VERSION ""

NS_ :

BS_:

BU_:

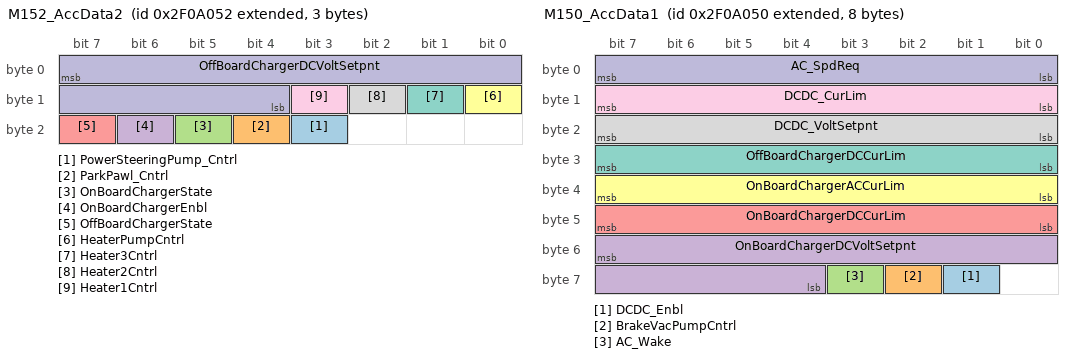
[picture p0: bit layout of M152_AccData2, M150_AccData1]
BO_ 2196807762 M152_AccData2: 3 Vector__XXX
 SG_ PowerSteeringPump_Cntrl : 19|1@0+ (1,0) [0|1] "unitless:" Vector__XXX
 SG_ ParkPawl_Cntrl : 20|1@0+ (1,0) [0|1] "unitless:" Vector__XXX
 SG_ OnBoardChargerState : 21|1@0+ (1,0) [0|1] "unitless:" Vector__XXX
 SG_ OnBoardChargerEnbl : 22|1@0+ (1,0) [0|1] "unitless:" Vector__XXX
 SG_ OffBoardChargerState : 23|1@0+ (1,0) [0|1] "unitless:" Vector__XXX
 SG_ HeaterPumpCntrl : 8|1@0+ (1,0) [0|1] "unitless:" Vector__XXX
 SG_ Heater3Cntrl : 9|1@0+ (1,0) [0|1] "unitless:" Vector__XXX
 SG_ Heater2Cntrl : 10|1@0+ (1,0) [0|1] "unitless:" Vector__XXX
 SG_ Heater1Cntrl : 11|1@0+ (1,0) [0|1] "unitless:" Vector__XXX
 SG_ OffBoardChargerDCVoltSetpnt : 7|12@0+ (0.5,0) [0|2047.5] "voltage:V" Vector__XXX

BO_ 2196807760 M150_AccData1: 8 Vector__XXX
 SG_ DCDC_Enbl : 57|1@0+ (1,0) [0|1] "unitless:" Vector__XXX
 SG_ BrakeVacPumpCntrl : 58|1@0+ (1,0) [0|1] "unitless:" Vector__XXX
 SG_ AC_Wake : 59|1@0+ (1,0) [0|1] "unitless:" Vector__XXX
 SG_ OnBoardChargerDCVoltSetpnt : 55|12@0+ (0.5,0) [0|2047.5] "voltage:V" Vector__XXX
 SG_ OnBoardChargerDCCurLim : 47|8@0+ (0.5,0) [0|127.5] "current:A" Vector__XXX
 SG_ OnBoardChargerACCurLim : 39|8@0+ (0.5,0) [0|127.5] "current:A" Vector__XXX
 SG_ OffBoardChargerDCCurLim : 31|8@0+ (0.5,0) [0|127.5] "current:A" Vector__XXX
 SG_ DCDC_VoltSetpnt : 23|8@0+ (0.1,0) [0|25.5] "voltage:V" Vector__XXX
 SG_ DCDC_CurLim : 15|8@0+ (0.5,0) [0|127.5] "current:A" Vector__XXX
 SG_ AC_SpdReq : 7|8@0+ (25,0) [0|6375] "angular_speed:rpm" Vector__XXX

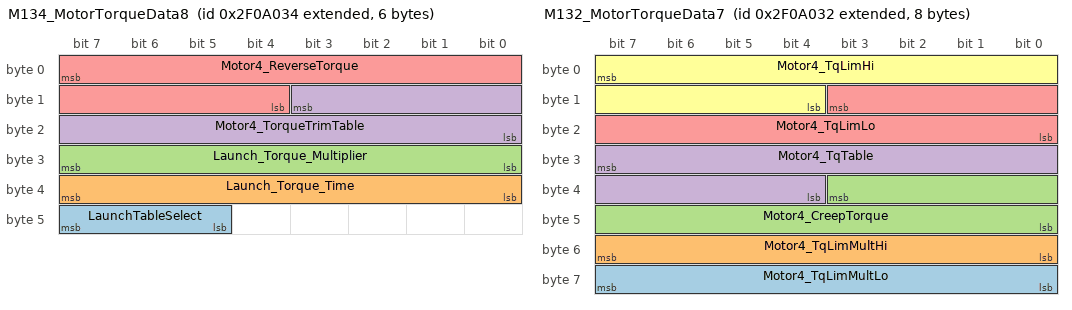
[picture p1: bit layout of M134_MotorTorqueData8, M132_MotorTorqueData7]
BO_ 2196807732 M134_MotorTorqueData8: 6 Vector__XXX
 SG_ LaunchTableSelect : 47|3@0+ (1,0) [0|7] "unitless:" Vector__XXX
 SG_ Launch_Torque_Time : 39|8@0+ (0.1,0) [0|25.5] "time:s" Vector__XXX
 SG_ Launch_Torque_Multiplier : 31|8@0+ (1,0) [0|255] "fraction:%" Vector__XXX
 SG_ Motor4_TorqueTrimTable : 11|12@0- (0.001,0) [-2.048|2.047] "fraction:frac" Vector__XXX
 SG_ Motor4_ReverseTorque : 7|12@0+ (0.1,0) [0|409.5] "torque:N.m" Vector__XXX

BO_ 2196807730 M132_MotorTorqueData7: 8 Vector__XXX
 SG_ Motor4_TqLimMultLo : 63|8@0+ (0.005,0) [0|1.275] "fraction:frac" Vector__XXX
 SG_ Motor4_TqLimMultHi : 55|8@0+ (0.005,0) [0|1.275] "fraction:frac" Vector__XXX
 SG_ Motor4_CreepTorque : 35|12@0+ (0.1,0) [0|409.5] "torque:N.m" Vector__XXX
 SG_ Motor4_TqTable : 31|12@0+ (0.5,0) [0|2047.5] "torque:N.m" Vector__XXX
 SG_ Motor4_TqLimLo : 11|12@0- (0.5,0) [-1024|1023.5] "torque:N.m" Vector__XXX
 SG_ Motor4_TqLimHi : 7|12@0+ (0.5,0) [0|2047.5] "torque:N.m" Vector__XXX

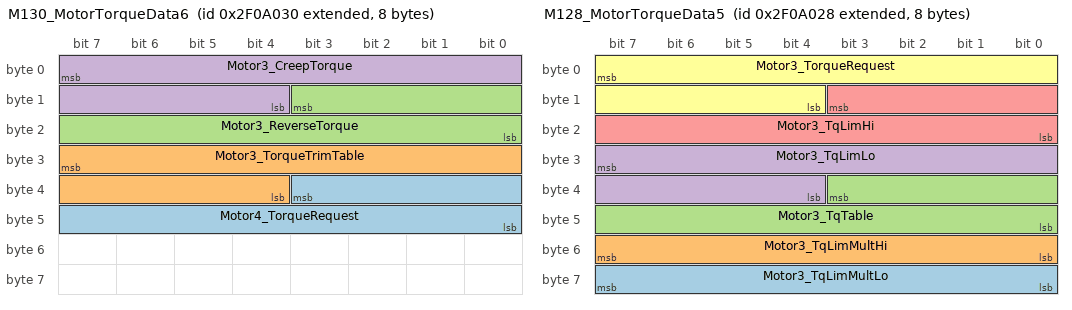
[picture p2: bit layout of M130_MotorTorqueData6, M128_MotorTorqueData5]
BO_ 2196807728 M130_MotorTorqueData6: 8 Vector__XXX
 SG_ Motor4_TorqueRequest : 35|12@0- (0.5,0) [-1024|1023.5] "torque:N.m" Vector__XXX
 SG_ Motor3_TorqueTrimTable : 31|12@0- (0.001,0) [-2.048|2.047] "fraction:frac" Vector__XXX
 SG_ Motor3_ReverseTorque : 11|12@0+ (0.1,0) [0|409.5] "torque:N.m" Vector__XXX
 SG_ Motor3_CreepTorque : 7|12@0+ (0.1,0) [0|409.5] "torque:N.m" Vector__XXX

BO_ 2196807720 M128_MotorTorqueData5: 8 Vector__XXX
 SG_ Motor3_TqLimMultLo : 63|8@0+ (0.005,0) [0|1.275] "fraction:frac" Vector__XXX
 SG_ Motor3_TqLimMultHi : 55|8@0+ (0.005,0) [0|1.275] "fraction:frac" Vector__XXX
 SG_ Motor3_TqTable : 35|12@0+ (0.5,0) [0|2047.5] "torque:N.m" Vector__XXX
 SG_ Motor3_TqLimLo : 31|12@0- (0.5,0) [-1024|1023.5] "torque:N.m" Vector__XXX
 SG_ Motor3_TqLimHi : 11|12@0+ (0.5,0) [0|2047.5] "torque:N.m" Vector__XXX
 SG_ Motor3_TorqueRequest : 7|12@0- (0.5,0) [-1024|1023.5] "torque:N.m" Vector__XXX

BO_ 2196807752 M148_VCU_FaultStates3_Reserved: 8 Vector__XXX

BO_ 2196807704 M118_VehicleInputs4: 4 Vector__XXX
 SG_ Vehicle_Odometer : 7|32@0+ (0.01,0) [0|42949672.95] "distance:mi" Vector__XXX

BO_ 2196807696 M110_DriverInputs3_Reserved: 8 Vector__XXX

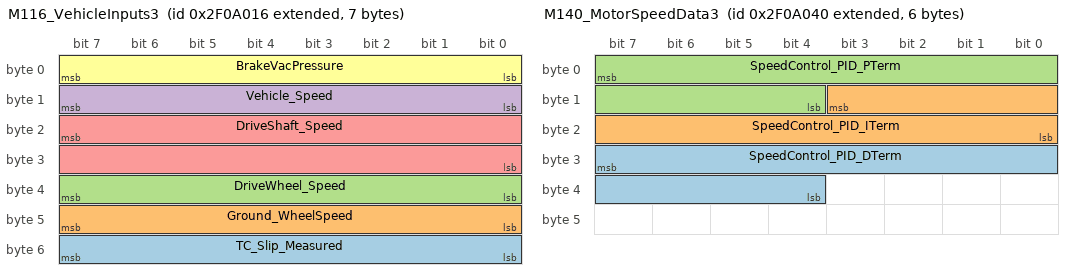
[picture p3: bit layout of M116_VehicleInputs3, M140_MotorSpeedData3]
BO_ 2196807702 M116_VehicleInputs3: 7 Vector__XXX
 SG_ TC_Slip_Measured : 55|8@0+ (1,0) [0|255] "speed:mph" Vector__XXX
 SG_ Ground_WheelSpeed : 47|8@0+ (1,0) [0|255] "speed:mph" Vector__XXX
 SG_ DriveWheel_Speed : 39|8@0+ (1,0) [0|255] "speed:mph" Vector__XXX
 SG_ Vehicle_Speed : 15|8@0+ (1,0) [0|255] "speed:mph" Vector__XXX
 SG_ DriveShaft_Speed : 23|16@0+ (1,0) [0|65535] "angular_speed:rpm" Vector__XXX
 SG_ BrakeVacPressure : 7|8@0+ (0.14504,-14.696) [-14.696|22.2892] "pressure_gauge:psi(g)" Vector__XXX

BO_ 2196807684 M104_VCU_States3: 8 Vector__XXX
 SG_ Run_Time_Counter : 55|16@0+ (1,0) [0|65535] "time:s" Vector__XXX
 SG_ LaunchRamp_Time : 47|8@0+ (0.1,0) [0|25.5] "time:s" Vector__XXX
 SG_ LaunchTimer_Running : 33|1@0+ (1,0) [0|1] "unitless:" Vector__XXX
 SG_ LimMult_MC4CurrRamp_Active : 34|1@0+ (1,0) [0|1] "unitless:" Vector__XXX
 SG_ LimMult_MC3CurrRamp_Active : 35|1@0+ (1,0) [0|1] "unitless:" Vector__XXX
 SG_ LimMult_MC2CurrRamp_Active : 36|1@0+ (1,0) [0|1] "unitless:" Vector__XXX
 SG_ LimMult_MC1CurrRamp_Active : 37|1@0+ (1,0) [0|1] "unitless:" Vector__XXX
 SG_ LimMult_VehSpd_Lo_Active : 38|1@0+ (1,0) [0|1] "unitless:" Vector__XXX
 SG_ LimMult_VehSpd_Hi_Active : 39|1@0+ (1,0) [0|1] "unitless:" Vector__XXX
 SG_ LimMult_Shift5_Tq_Active : 24|1@0+ (1,0) [0|1] "unitless:" Vector__XXX
 SG_ LimMult_Shift4_Tq_Active : 25|1@0+ (1,0) [0|1] "unitless:" Vector__XXX
 SG_ LimMult_Shift3_Tq_Active : 26|1@0+ (1,0) [0|1] "unitless:" Vector__XXX
 SG_ LimMult_Shift2_Tq_Active : 27|1@0+ (1,0) [0|1] "unitless:" Vector__XXX
 SG_ LimMult_Shift1_Tq_Active : 28|1@0+ (1,0) [0|1] "unitless:" Vector__XXX
 SG_ LimMult_Pack_Voltage_Active : 29|1@0+ (1,0) [0|1] "unitless:" Vector__XXX
 SG_ LimMult_Pack_TempLo_Active : 30|1@0+ (1,0) [0|1] "unitless:" Vector__XXX
 SG_ LimMult_Pack_TempHi_Active : 31|1@0+ (1,0) [0|1] "unitless:" Vector__XXX
 SG_ LimMult_Pack_Current_Active : 16|1@0+ (1,0) [0|1] "unitless:" Vector__XXX
 SG_ LimMult_Over_rev_Active : 17|1@0+ (1,0) [0|1] "unitless:" Vector__XXX
 SG_ LimMult_Motor4_Temp_Active : 18|1@0+ (1,0) [0|1] "unitless:" Vector__XXX
 SG_ LimMult_Motor4_SpdLo_Active : 19|1@0+ (1,0) [0|1] "unitless:" Vector__XXX
 SG_ LimMult_Motor3_Temp_Active : 20|1@0+ (1,0) [0|1] "unitless:" Vector__XXX
 SG_ LimMult_Motor3_SpdLo_Active : 21|1@0+ (1,0) [0|1] "unitless:" Vector__XXX
 SG_ LimMult_Motor2_Temp_Active : 22|1@0+ (1,0) [0|1] "unitless:" Vector__XXX
 SG_ LimMult_Motor2_SpdLo_Active : 23|1@0+ (1,0) [0|1] "unitless:" Vector__XXX
 SG_ LimMult_Motor1_Temp_Active : 8|1@0+ (1,0) [0|1] "unitless:" Vector__XXX
 SG_ LimMult_Motor1_SpdLo_Active : 9|1@0+ (1,0) [0|1] "unitless:" Vector__XXX
 SG_ LimMult_MC4Temp_Active : 10|1@0+ (1,0) [0|1] "unitless:" Vector__XXX
 SG_ LimMult_MC4Curr_Active : 11|1@0+ (1,0) [0|1] "unitless:" Vector__XXX
 SG_ LimMult_MC3Temp_Active : 12|1@0+ (1,0) [0|1] "unitless:" Vector__XXX
 SG_ LimMult_MC3Curr_Active : 13|1@0+ (1,0) [0|1] "unitless:" Vector__XXX
 SG_ LimMult_MC2Temp_Active : 14|1@0+ (1,0) [0|1] "unitless:" Vector__XXX
 SG_ LimMult_MC2Curr_Active : 15|1@0+ (1,0) [0|1] "unitless:" Vector__XXX
 SG_ LimMult_MC1Temp_Active : 0|1@0+ (1,0) [0|1] "unitless:" Vector__XXX
 SG_ LimMult_MC1Curr_Active : 1|1@0+ (1,0) [0|1] "unitless:" Vector__XXX
 SG_ LimMult_Launch_Time_Active : 2|1@0+ (1,0) [0|1] "unitless:" Vector__XXX
 SG_ LimMult_DriveShaft_Spd_Active : 3|1@0+ (1,0) [0|1] "unitless:" Vector__XXX
 SG_ LimMult_CellVolt_Min_Active : 4|1@0+ (1,0) [0|1] "unitless:" Vector__XXX
 SG_ LimMult_CellVolt_Max_Active : 5|1@0+ (1,0) [0|1] "unitless:" Vector__XXX
 SG_ LimMult_Batt_SOC_Active : 6|1@0+ (1,0) [0|1] "unitless:" Vector__XXX
 SG_ LimMult_Batt_DCL_Active : 7|1@0+ (1,0) [0|1] "unitless:" Vector__XXX

BO_ 2196807746 M142_MotorSpeedData4_Reserved: 8 Vector__XXX

BO_ 2196807744 M140_MotorSpeedData3: 6 Vector__XXX
 SG_ SpeedControl_PID_DTerm : 31|12@0- (0.5,0) [-1024|1023.5] "torque:N.m" Vector__XXX
 SG_ SpeedControl_PID_ITerm : 11|12@0- (0.5,0) [-1024|1023.5] "torque:N.m" Vector__XXX
 SG_ SpeedControl_PID_PTerm : 7|12@0- (0.5,0) [-1024|1023.5] "torque:N.m" Vector__XXX

BO_ 2196807750 M146_VCU_FaultStates2_Reserved: 8 Vector__XXX

BO_ 2196807748 M144_VCU_FaultStates1: 7 Vector__XXX
 SG_ Fault_Wheel_Speed_NR_Spike : 48|1@0+ (1,0) [0|1] "unitless:" Vector__XXX
 SG_ Fault_Wheel_Speed_NL_Spike : 49|1@0+ (1,0) [0|1] "unitless:" Vector__XXX
 SG_ Fault_Wheel_Speed_DR_Spike : 50|1@0+ (1,0) [0|1] "unitless:" Vector__XXX
 SG_ Fault_Wheel_Speed_DL_Spike : 51|1@0+ (1,0) [0|1] "unitless:" Vector__XXX
 SG_ Fault_Wheel_Speed_DD_Spike : 52|1@0+ (1,0) [0|1] "unitless:" Vector__XXX
 SG_ Fault_WheelBar_Press2_InputLo : 53|1@0+ (1,0) [0|1] "unitless:" Vector__XXX
 SG_ Fault_WheelBar_Press2_InputHi : 54|1@0+ (1,0) [0|1] "unitless:" Vector__XXX
 SG_ Fault_WheelBar_Press1_InputLo : 55|1@0+ (1,0) [0|1] "unitless:" Vector__XXX
 SG_ Fault_WheelBar_Press1_InputHi : 40|1@0+ (1,0) [0|1] "unitless:" Vector__XXX
 SG_ Fault_Trans_Temp_InputLo : 41|1@0+ (1,0) [0|1] "unitless:" Vector__XXX
 SG_ Fault_Trans_Temp_InputHi : 42|1@0+ (1,0) [0|1] "unitless:" Vector__XXX
 SG_ Fault_Trans_Press_InputLo : 43|1@0+ (1,0) [0|1] "unitless:" Vector__XXX
 SG_ Fault_Trans_Press_InputHi : 44|1@0+ (1,0) [0|1] "unitless:" Vector__XXX
 SG_ Fault_TransBrk_Sol : 45|1@0+ (1,0) [0|1] "unitless:" Vector__XXX
 SG_ Fault_Shift_Sol : 46|1@0+ (1,0) [0|1] "unitless:" Vector__XXX
 SG_ Fault_Reverse_Lamps : 47|1@0+ (1,0) [0|1] "unitless:" Vector__XXX
 SG_ Fault_Regen_LeverXChk : 32|1@0+ (1,0) [0|1] "unitless:" Vector__XXX
 SG_ Fault_Park_Lamps : 33|1@0+ (1,0) [0|1] "unitless:" Vector__XXX
 SG_ Fault_Manual_Regen2_Spike : 34|1@0+ (1,0) [0|1] "unitless:" Vector__XXX
 SG_ Fault_Manual_Regen2_InputLo : 35|1@0+ (1,0) [0|1] "unitless:" Vector__XXX
 SG_ Fault_Manual_Regen2_InputHi : 36|1@0+ (1,0) [0|1] "unitless:" Vector__XXX
 SG_ Fault_Manual_Regen1_Spike : 37|1@0+ (1,0) [0|1] "unitless:" Vector__XXX
 SG_ Fault_Manual_Regen1_InputLo : 38|1@0+ (1,0) [0|1] "unitless:" Vector__XXX
 SG_ Fault_Manual_Regen1_InputHi : 39|1@0+ (1,0) [0|1] "unitless:" Vector__XXX
 SG_ Fault_LineLock_Sol : 24|1@0+ (1,0) [0|1] "unitless:" Vector__XXX
 SG_ Fault_MC5SupplyVoltageLow : 25|1@0+ (1,0) [0|1] "unitless:" Vector__XXX
 SG_ Fault_MC4SupplyVoltageLow : 26|1@0+ (1,0) [0|1] "unitless:" Vector__XXX
 SG_ Fault_MC4_Contactor : 27|1@0+ (1,0) [0|1] "unitless:" Vector__XXX
 SG_ Fault_MC3SupplyVoltageLow : 28|1@0+ (1,0) [0|1] "unitless:" Vector__XXX
 SG_ Fault_MC3_Contactor : 29|1@0+ (1,0) [0|1] "unitless:" Vector__XXX
 SG_ Fault_MC2SupplyVoltageLow : 30|1@0+ (1,0) [0|1] "unitless:" Vector__XXX
 SG_ Fault_MC2_Contactor : 31|1@0+ (1,0) [0|1] "unitless:" Vector__XXX
 SG_ Fault_MC1SupplyVoltageLow : 16|1@0+ (1,0) [0|1] "unitless:" Vector__XXX
 SG_ Fault_MC1_Contactor : 17|1@0+ (1,0) [0|1] "unitless:" Vector__XXX
 SG_ Fault_IgnChgPlug_XCheck : 18|1@0+ (1,0) [0|1] "unitless:" Vector__XXX
 SG_ Fault_Idle_Target : 19|1@0+ (1,0) [0|1] "unitless:" Vector__XXX
 SG_ Fault_Head_Lamps : 20|1@0+ (1,0) [0|1] "unitless:" Vector__XXX
 SG_ Fault_DCVoltage_SafeLight : 21|1@0+ (1,0) [0|1] "unitless:" Vector__XXX
 SG_ Fault_Cool_Temp2_InputLo : 22|1@0+ (1,0) [0|1] "unitless:" Vector__XXX
 SG_ Fault_Cool_Temp2_InputHi : 23|1@0+ (1,0) [0|1] "unitless:" Vector__XXX
 SG_ Fault_Cool_Temp1_InputLo : 8|1@0+ (1,0) [0|1] "unitless:" Vector__XXX
 SG_ Fault_Cool_Temp1_InputHi : 9|1@0+ (1,0) [0|1] "unitless:" Vector__XXX
 SG_ Fault_Cooling_Pump2 : 10|1@0+ (1,0) [0|1] "unitless:" Vector__XXX
 SG_ Fault_Cooling_Pump1 : 11|1@0+ (1,0) [0|1] "unitless:" Vector__XXX
 SG_ Fault_Brk_Press_InputLo : 12|1@0+ (1,0) [0|1] "unitless:" Vector__XXX
 SG_ Fault_Brk_Press_InputHi : 13|1@0+ (1,0) [0|1] "unitless:" Vector__XXX
 SG_ Fault_Brake_Lamps : 14|1@0+ (1,0) [0|1] "unitless:" Vector__XXX
 SG_ Fault_AccelPedal_XCheck : 15|1@0+ (1,0) [0|1] "unitless:" Vector__XXX
 SG_ Fault_AccPedal2_Spike : 0|1@0+ (1,0) [0|1] "unitless:" Vector__XXX
 SG_ Fault_AccPedal2_InputLo : 1|1@0+ (1,0) [0|1] "unitless:" Vector__XXX
 SG_ Fault_AccPedal2_InputHi : 2|1@0+ (1,0) [0|1] "unitless:" Vector__XXX
 SG_ Fault_AccPedal1_Spike : 3|1@0+ (1,0) [0|1] "unitless:" Vector__XXX
 SG_ Fault_AccPedal1_Input_Lo : 4|1@0+ (1,0) [0|1] "unitless:" Vector__XXX
 SG_ Fault_AccPedal1_Input_Hi : 5|1@0+ (1,0) [0|1] "unitless:" Vector__XXX
 SG_ Fault_Acc_Power : 6|1@0+ (1,0) [0|1] "unitless:" Vector__XXX
 SG_ Fault_Acc_LED : 7|1@0+ (1,0) [0|1] "unitless:" Vector__XXX

BO_ 2196807682 M102_VCU_States2: 8 Vector__XXX
 SG_ Contactors_Enabled : 56|1@0+ (1,0) [0|1] "unitless:" Vector__XXX
 SG_ ChargeContactorCntrl : 57|1@0+ (1,0) [0|1] "unitless:" Vector__XXX
 SG_ Acc_PowerCntrl : 58|1@0+ (1,0) [0|1] "unitless:" Vector__XXX
 SG_ Acc_LightCntrl : 59|1@0+ (1,0) [0|1] "unitless:" Vector__XXX
 SG_ ReverseLamps_Cntrl : 60|1@0+ (1,0) [0|1] "unitless:" Vector__XXX
 SG_ ParkLamps_Cntrl : 61|1@0+ (1,0) [0|1] "unitless:" Vector__XXX
 SG_ HVSafetyLight_Cntrl : 62|1@0+ (1,0) [0|1] "unitless:" Vector__XXX
 SG_ Head_LampsCntrl : 63|1@0+ (1,0) [0|1] "unitless:" Vector__XXX
 SG_ Brake_LampsCntrl : 48|1@0+ (1,0) [0|1] "unitless:" Vector__XXX
 SG_ TransBrake_Switch : 49|1@0+ (1,0) [0|1] "unitless:" Vector__XXX
 SG_ LineLock_Switch : 50|1@0+ (1,0) [0|1] "unitless:" Vector__XXX
 SG_ Inertia_Switch : 51|1@0+ (1,0) [0|1] "unitless:" Vector__XXX
 SG_ IMDState : 52|1@0+ (1,0) [0|1] "unitless:" Vector__XXX
 SG_ ShiftSol_Cntrl : 53|1@0+ (1,0) [0|1] "unitless:" Vector__XXX
 SG_ Shift_Sol2 : 54|1@0+ (1,0) [0|1] "unitless:" Vector__XXX
 SG_ Shift_Sol1 : 55|1@0+ (1,0) [0|1] "unitless:" Vector__XXX
 SG_ LineLock_Cntrl : 32|1@0+ (1,0) [0|1] "unitless:" Vector__XXX
 SG_ TransBrake_Cntrl : 33|1@0+ (1,0) [0|1] "unitless:" Vector__XXX
 SG_ Cool_PumpSpdTarget : 47|8@0+ (25,0) [0|6375] "angular_speed:rpm" Vector__XXX
 SG_ Cool_Pump_Wake : 34|1@0+ (1,0) [0|1] "unitless:" Vector__XXX
 SG_ Cool_Pump2_Cntrl : 35|1@0+ (1,0) [0|1] "unitless:" Vector__XXX
 SG_ Cool_Pump1_Cntrl : 36|1@0+ (1,0) [0|1] "unitless:" Vector__XXX
 SG_ OilPump1_On : 37|1@0+ (1,0) [0|1] "unitless:" Vector__XXX
 SG_ Cool_Fan2_On : 38|1@0+ (1,0) [0|1] "unitless:" Vector__XXX
 SG_ Cool_Fan1_On : 39|1@0+ (1,0) [0|1] "unitless:" Vector__XXX
 SG_ SpeedMode_Allowed : 24|1@0+ (1,0) [0|1] "unitless:" Vector__XXX
 SG_ InvControl_Mode : 25|1@0+ (1,0) [0|1] "unitless:" Vector__XXX
 SG_ Launch_Mode : 26|1@0+ (1,0) [0|1] "unitless:" Vector__XXX
 SG_ Burnout_Mode : 27|1@0+ (1,0) [0|1] "unitless:" Vector__XXX
 SG_ Idle_Mode : 28|1@0+ (1,0) [0|1] "unitless:" Vector__XXX
 SG_ Creep_Mode : 29|1@0+ (1,0) [0|1] "unitless:" Vector__XXX
 SG_ MC4_PreChgComplete : 30|1@0+ (1,0) [0|1] "unitless:" Vector__XXX
 SG_ MC4_PreChg_Cmd : 31|1@0+ (1,0) [0|1] "unitless:" Vector__XXX
 SG_ MC4_Pos_Cmd : 16|1@0+ (1,0) [0|1] "unitless:" Vector__XXX
 SG_ MC3_PreChgComplete : 17|1@0+ (1,0) [0|1] "unitless:" Vector__XXX
 SG_ MC3_PreChg_Cmd : 18|1@0+ (1,0) [0|1] "unitless:" Vector__XXX
 SG_ MC3_Pos_Cmd : 19|1@0+ (1,0) [0|1] "unitless:" Vector__XXX
 SG_ MC2_PreChgComplete : 20|1@0+ (1,0) [0|1] "unitless:" Vector__XXX
 SG_ MC2_PreChg_Cmd : 21|1@0+ (1,0) [0|1] "unitless:" Vector__XXX
 SG_ MC2_Pos_Cmd : 22|1@0+ (1,0) [0|1] "unitless:" Vector__XXX
 SG_ MC1_PreChgComplete : 23|1@0+ (1,0) [0|1] "unitless:" Vector__XXX
 SG_ MC1_PreChg_Cmd : 8|1@0+ (1,0) [0|1] "unitless:" Vector__XXX
 SG_ MC1_Pos_Cmd : 9|1@0+ (1,0) [0|1] "unitless:" Vector__XXX
 SG_ VCU_5V_Output : 15|6@0+ (0.1,0) [0|6.3] "voltage:V" Vector__XXX
 SG_ VCU_12V_Input : 7|8@0+ (0.1,0) [0|25.5] "voltage:V" Vector__XXX

BO_ 2196807688 M108_DriverInputs2: 4 Vector__XXX
 SG_ CCSetCst : 28|1@0+ (1,0) [0|1] "unitless:" Vector__XXX
 SG_ CCRsmAcc : 29|1@0+ (1,0) [0|1] "unitless:" Vector__XXX
 SG_ CCOn : 30|1@0+ (1,0) [0|1] "unitless:" Vector__XXX
 SG_ CCCancel : 31|1@0+ (1,0) [0|1] "unitless:" Vector__XXX
 SG_ Logging_Switch : 16|1@0+ (1,0) [0|1] "unitless:" Vector__XXX
 SG_ Wake_Switch : 17|1@0+ (1,0) [0|1] "unitless:" Vector__XXX
 SG_ Acc_LightSwitch : 18|1@0+ (1,0) [0|1] "unitless:" Vector__XXX
 SG_ ACSwitch : 19|1@0+ (1,0) [0|1] "unitless:" Vector__XXX
 SG_ HeaterSwitch : 20|1@0+ (1,0) [0|1] "unitless:" Vector__XXX
 SG_ Cooling_PumpOrdSwitch : 21|1@0+ (1,0) [0|1] "unitless:" Vector__XXX
 SG_ Cooling_FanOrdSwitch : 22|1@0+ (1,0) [0|1] "unitless:" Vector__XXX
 SG_ Enable_Switch : 23|1@0+ (1,0) [0|1] "unitless:" Vector__XXX
 SG_ ParkLamp_Switch : 8|1@0+ (1,0) [0|1] "unitless:" Vector__XXX
 SG_ Head_LampSwitch : 9|1@0+ (1,0) [0|1] "unitless:" Vector__XXX
 SG_ Reverse_Switch : 10|1@0+ (1,0) [0|1] "unitless:" Vector__XXX
 SG_ Drive_Switch : 11|1@0+ (1,0) [0|1] "unitless:" Vector__XXX
 SG_ Neutral_Switch : 12|1@0+ (1,0) [0|1] "unitless:" Vector__XXX
 SG_ Park_Switch : 13|1@0+ (1,0) [0|1] "unitless:" Vector__XXX
 SG_ Manual_Regen2Valid : 14|1@0+ (1,0) [0|1] "unitless:" Vector__XXX
 SG_ Manual_Regen1Valid : 15|1@0+ (1,0) [0|1] "unitless:" Vector__XXX
 SG_ ManRegen_XCheckDiff : 7|8@0+ (0.39215686,0) [0|99.9999993] "fraction:%" Vector__XXX

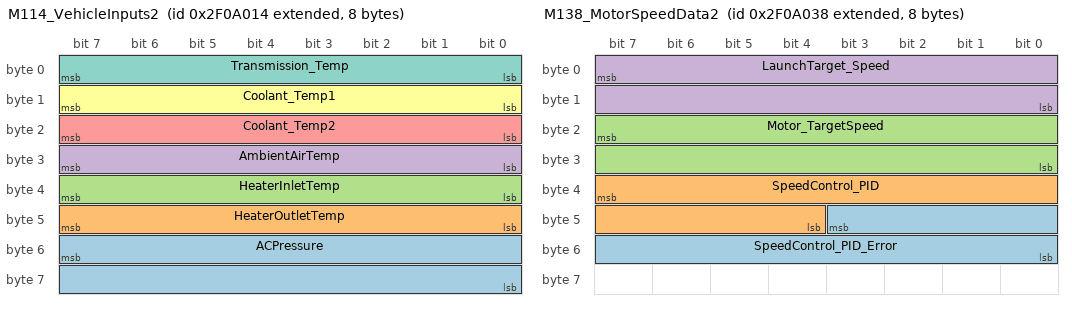
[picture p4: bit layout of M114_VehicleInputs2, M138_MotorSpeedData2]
BO_ 2196807700 M114_VehicleInputs2: 8 Vector__XXX
 SG_ ACPressure : 55|16@0+ (0.1,0) [0|6553.5] "pressure_gauge:psi(g)" Vector__XXX
 SG_ HeaterOutletTemp : 47|8@0- (1,0) [-128|127] "temperature:C" Vector__XXX
 SG_ HeaterInletTemp : 39|8@0- (1,0) [-128|127] "temperature:C" Vector__XXX
 SG_ AmbientAirTemp : 31|8@0- (1,0) [-128|127] "temperature:C" Vector__XXX
 SG_ Coolant_Temp2 : 23|8@0- (1,0) [-128|127] "temperature:C" Vector__XXX
 SG_ Coolant_Temp1 : 15|8@0- (1,0) [-128|127] "temperature:C" Vector__XXX
 SG_ Transmission_Temp : 7|8@0+ (1,-50) [-50|205] "temperature:C" Vector__XXX

BO_ 2196807736 M138_MotorSpeedData2: 8 Vector__XXX
 SG_ SpeedControl_PID_Error : 43|12@0- (0.5,0) [-1024|1023.5] "torque:N.m" Vector__XXX
 SG_ SpeedControl_PID : 39|12@0- (0.5,0) [-1024|1023.5] "torque:N.m" Vector__XXX
 SG_ Motor_TargetSpeed : 23|16@0+ (0.25,0) [0|16383.75] "angular_speed:rpm" Vector__XXX
 SG_ LaunchTarget_Speed : 7|16@0+ (0.25,0) [0|16383.75] "angular_speed:rpm" Vector__XXX

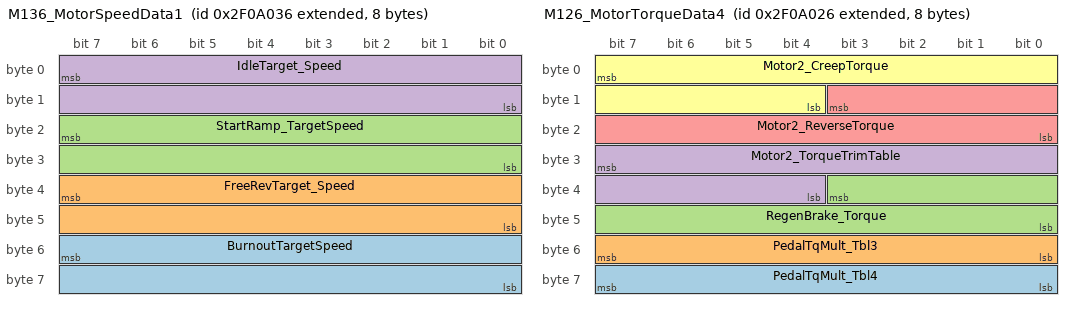
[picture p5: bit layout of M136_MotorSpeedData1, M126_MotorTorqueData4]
BO_ 2196807734 M136_MotorSpeedData1: 8 Vector__XXX
 SG_ BurnoutTargetSpeed : 55|16@0+ (0.25,0) [0|16383.75] "angular_speed:rpm" Vector__XXX
 SG_ FreeRevTarget_Speed : 39|16@0+ (0.25,0) [0|16383.75] "angular_speed:rpm" Vector__XXX
 SG_ StartRamp_TargetSpeed : 23|16@0+ (0.25,0) [0|16383.75] "angular_speed:rpm" Vector__XXX
 SG_ IdleTarget_Speed : 7|16@0+ (0.25,0) [0|16383.75] "angular_speed:rpm" Vector__XXX

BO_ 2196807718 M126_MotorTorqueData4: 8 Vector__XXX
 SG_ PedalTqMult_Tbl4 : 63|8@0- (1,0) [-128|127] "fraction:%" Vector__XXX
 SG_ PedalTqMult_Tbl3 : 55|8@0- (1,0) [-128|127] "fraction:%" Vector__XXX
 SG_ RegenBrake_Torque : 35|12@0+ (0.5,0) [0|2047.5] "torque:N.m" Vector__XXX
 SG_ Motor2_TorqueTrimTable : 31|12@0- (0.001,0) [-2.048|2.047] "fraction:frac" Vector__XXX
 SG_ Motor2_ReverseTorque : 11|12@0+ (0.1,0) [0|409.5] "torque:N.m" Vector__XXX
 SG_ Motor2_CreepTorque : 7|12@0+ (0.1,0) [0|409.5] "torque:N.m" Vector__XXX

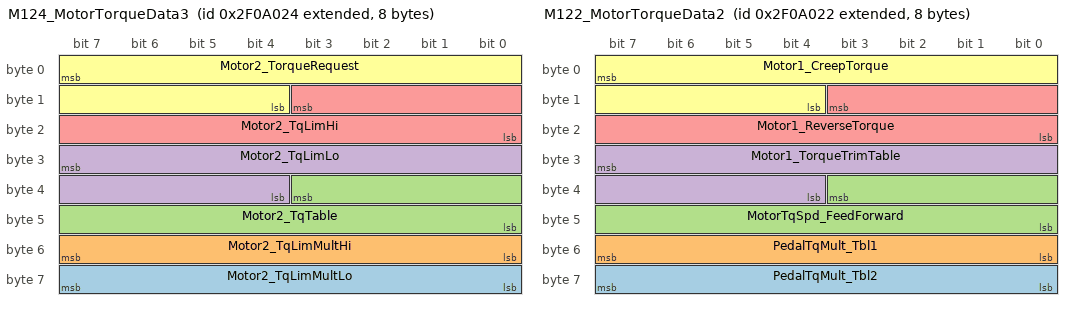
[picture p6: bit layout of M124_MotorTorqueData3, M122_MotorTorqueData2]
BO_ 2196807716 M124_MotorTorqueData3: 8 Vector__XXX
 SG_ Motor2_TqLimMultLo : 63|8@0+ (0.005,0) [0|1.275] "fraction:frac" Vector__XXX
 SG_ Motor2_TqLimMultHi : 55|8@0+ (0.005,0) [0|1.275] "fraction:frac" Vector__XXX
 SG_ Motor2_TqTable : 35|12@0+ (0.5,0) [0|2047.5] "torque:N.m" Vector__XXX
 SG_ Motor2_TqLimLo : 31|12@0- (0.5,0) [-1024|1023.5] "torque:N.m" Vector__XXX
 SG_ Motor2_TqLimHi : 11|12@0+ (0.5,0) [0|2047.5] "torque:N.m" Vector__XXX
 SG_ Motor2_TorqueRequest : 7|12@0- (0.5,0) [-1024|1023.5] "torque:N.m" Vector__XXX

BO_ 2196807714 M122_MotorTorqueData2: 8 Vector__XXX
 SG_ PedalTqMult_Tbl2 : 63|8@0- (1,0) [-128|127] "fraction:%" Vector__XXX
 SG_ PedalTqMult_Tbl1 : 55|8@0- (1,0) [-128|127] "fraction:%" Vector__XXX
 SG_ MotorTqSpd_FeedForward : 35|12@0+ (0.5,0) [0|2047.5] "torque:N.m" Vector__XXX
 SG_ Motor1_TorqueTrimTable : 31|12@0- (0.001,0) [-2.048|2.047] "fraction:frac" Vector__XXX
 SG_ Motor1_ReverseTorque : 11|12@0+ (0.1,0) [0|409.5] "torque:N.m" Vector__XXX
 SG_ Motor1_CreepTorque : 7|12@0+ (0.1,0) [0|409.5] "torque:N.m" Vector__XXX

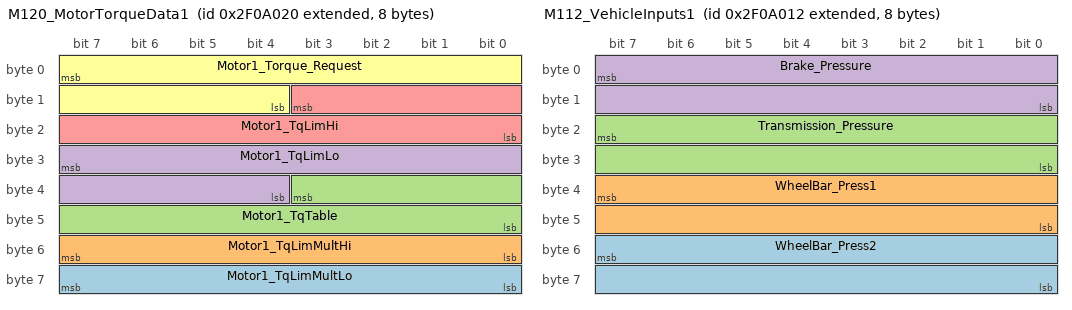
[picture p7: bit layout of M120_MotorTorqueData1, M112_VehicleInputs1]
BO_ 2196807712 M120_MotorTorqueData1: 8 Vector__XXX
 SG_ Motor1_TqLimMultLo : 63|8@0+ (0.005,0) [0|1.275] "fraction:frac" Vector__XXX
 SG_ Motor1_TqLimMultHi : 55|8@0+ (0.005,0) [0|1.275] "fraction:frac" Vector__XXX
 SG_ Motor1_TqTable : 35|12@0+ (0.5,0) [0|2047.5] "torque:N.m" Vector__XXX
 SG_ Motor1_TqLimLo : 31|12@0- (0.5,0) [-1024|1023.5] "torque:N.m" Vector__XXX
 SG_ Motor1_TqLimHi : 11|12@0+ (0.5,0) [0|2047.5] "torque:N.m" Vector__XXX
 SG_ Motor1_Torque_Request : 7|12@0- (0.5,0) [-1024|1023.5] "torque:N.m" Vector__XXX

BO_ 2196807698 M112_VehicleInputs1: 8 Vector__XXX
 SG_ WheelBar_Press2 : 55|16@0+ (0.1,0) [0|6553.5] "pressure_gauge:psi(g)" Vector__XXX
 SG_ WheelBar_Press1 : 39|16@0+ (0.1,0) [0|6553.5] "pressure_gauge:psi(g)" Vector__XXX
 SG_ Transmission_Pressure : 23|16@0+ (0.1,0) [0|6553.5] "pressure_gauge:psi(g)" Vector__XXX
 SG_ Brake_Pressure : 7|16@0+ (0.1,0) [0|6553.5] "pressure_gauge:psi(g)" Vector__XXX

BO_ 2196807680 M100_VCU_States1: 8 Vector__XXX
 SG_ Performance_Level : 58|3@0+ (1,0) [0|7] "unitless:" Vector__XXX
 SG_ MC4_PreChgFB : 59|1@0+ (1,0) [0|1] "unitless:" Vector__XXX
 SG_ MC4_PosFB : 60|1@0+ (1,0) [0|1] "unitless:" Vector__XXX
 SG_ MC4_NegFB : 61|1@0+ (1,0) [0|1] "unitless:" Vector__XXX
 SG_ MC4_HVDetect : 62|1@0+ (1,0) [0|1] "unitless:" Vector__XXX
 SG_ MC3_PreChgFB : 63|1@0+ (1,0) [0|1] "unitless:" Vector__XXX
 SG_ MC3_PosFB : 48|1@0+ (1,0) [0|1] "unitless:" Vector__XXX
 SG_ MC3_NegFB : 49|1@0+ (1,0) [0|1] "unitless:" Vector__XXX
 SG_ MC3_HVDetect : 50|1@0+ (1,0) [0|1] "unitless:" Vector__XXX
 SG_ MC2_PreChgFB : 51|1@0+ (1,0) [0|1] "unitless:" Vector__XXX
 SG_ MC2_PosFB : 52|1@0+ (1,0) [0|1] "unitless:" Vector__XXX
 SG_ MC2_NegFB : 53|1@0+ (1,0) [0|1] "unitless:" Vector__XXX
 SG_ MC2_HVDetect : 54|1@0+ (1,0) [0|1] "unitless:" Vector__XXX
 SG_ MC1_PreChgFB : 55|1@0+ (1,0) [0|1] "unitless:" Vector__XXX
 SG_ MC1_PosFB : 40|1@0+ (1,0) [0|1] "unitless:" Vector__XXX
 SG_ MC1_NegFB : 41|1@0+ (1,0) [0|1] "unitless:" Vector__XXX
 SG_ MC1_HVDetect : 42|1@0+ (1,0) [0|1] "unitless:" Vector__XXX
 SG_ MC4_DCVoltageSafeState : 43|1@0+ (1,0) [0|1] "unitless:" Vector__XXX
 SG_ MC3_DCVoltageSafeState : 44|1@0+ (1,0) [0|1] "unitless:" Vector__XXX
 SG_ MC2_DCVoltageSafeState : 45|1@0+ (1,0) [0|1] "unitless:" Vector__XXX
 SG_ MC1_DCVoltageSafeState : 46|1@0+ (1,0) [0|1] "unitless:" Vector__XXX
 SG_ MC4ContEnable : 47|1@0+ (1,0) [0|1] "unitless:" Vector__XXX
 SG_ MC3ContEnable : 32|1@0+ (1,0) [0|1] "unitless:" Vector__XXX
 SG_ MC2ContEnable : 33|1@0+ (1,0) [0|1] "unitless:" Vector__XXX
 SG_ MC1ContEnable : 34|1@0+ (1,0) [0|1] "unitless:" Vector__XXX
 SG_ PumpCont_XCheck : 35|1@0+ (1,0) [0|1] "unitless:" Vector__XXX
 SG_ HVIL_Charge : 36|1@0+ (1,0) [0|1] "unitless:" Vector__XXX
 SG_ HVIL_Main : 37|1@0+ (1,0) [0|1] "unitless:" Vector__XXX
 SG_ MC4DischargeCmd : 38|1@0+ (1,0) [0|1] "unitless:" Vector__XXX
 SG_ MC3DischargeCmd : 39|1@0+ (1,0) [0|1] "unitless:" Vector__XXX
 SG_ MC2DischargeCmd : 24|1@0+ (1,0) [0|1] "unitless:" Vector__XXX
 SG_ MC1DischargeCmd : 25|1@0+ (1,0) [0|1] "unitless:" Vector__XXX
 SG_ MCPower : 26|1@0+ (1,0) [0|1] "unitless:" Vector__XXX
 SG_ MC4Enable : 27|1@0+ (1,0) [0|1] "unitless:" Vector__XXX
 SG_ MC3Enable : 28|1@0+ (1,0) [0|1] "unitless:" Vector__XXX
 SG_ MC2Enable : 29|1@0+ (1,0) [0|1] "unitless:" Vector__XXX
 SG_ MC1Enable : 30|1@0+ (1,0) [0|1] "unitless:" Vector__XXX
 SG_ Start_Safe : 31|1@0+ (1,0) [0|1] "unitless:" Vector__XXX
 SG_ Stop_Command_State : 16|1@0+ (1,0) [0|1] "unitless:" Vector__XXX
 SG_ Start_Command_State : 17|1@0+ (1,0) [0|1] "unitless:" Vector__XXX
 SG_ OPState : 23|6@0+ (1,0) [0|63] "unitless:" Vector__XXX
 SG_ Run_Mode_State : 9|2@0+ (1,0) [0|3] "unitless:" Vector__XXX
 SG_ Drive_Mode_State : 13|4@0+ (1,0) [0|15] "unitless:" Vector__XXX
 SG_ Run_Time : 7|10@0+ (1,0) [0|1023] "time:s" Vector__XXX

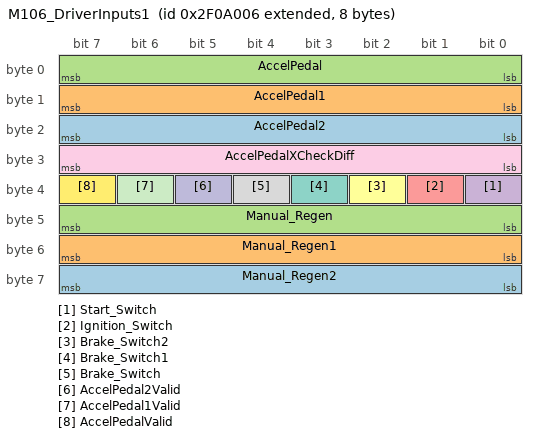
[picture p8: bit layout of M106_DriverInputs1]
BO_ 2196807686 M106_DriverInputs1: 8 Vector__XXX
 SG_ Manual_Regen2 : 63|8@0+ (0.39215686,0) [0|99.9999993] "fraction:%" Vector__XXX
 SG_ Manual_Regen1 : 55|8@0+ (0.39215686,0) [0|99.9999993] "fraction:%" Vector__XXX
 SG_ Manual_Regen : 47|8@0+ (0.39215686,0) [0|99.9999993] "fraction:%" Vector__XXX
 SG_ Start_Switch : 32|1@0+ (1,0) [0|1] "unitless:" Vector__XXX
 SG_ Ignition_Switch : 33|1@0+ (1,0) [0|1] "unitless:" Vector__XXX
 SG_ Brake_Switch2 : 34|1@0+ (1,0) [0|1] "unitless:" Vector__XXX
 SG_ Brake_Switch1 : 35|1@0+ (1,0) [0|1] "unitless:" Vector__XXX
 SG_ Brake_Switch : 36|1@0+ (1,0) [0|1] "unitless:" Vector__XXX
 SG_ AccelPedalXCheckDiff : 31|8@0+ (0.39215686,0) [0|99.9999993] "fraction:%" Vector__XXX
 SG_ AccelPedal2Valid : 37|1@0+ (1,0) [0|1] "unitless:" Vector__XXX
 SG_ AccelPedal1Valid : 38|1@0+ (1,0) [0|1] "unitless:" Vector__XXX
 SG_ AccelPedalValid : 39|1@0+ (1,0) [0|1] "unitless:" Vector__XXX
 SG_ AccelPedal2 : 23|8@0+ (0.39215686,0) [0|99.9999993] "fraction:%" Vector__XXX
 SG_ AccelPedal1 : 15|8@0+ (0.39215686,0) [0|99.9999993] "fraction:%" Vector__XXX
 SG_ AccelPedal : 7|8@0+ (0.39215686,0) [0|99.9999993] "fraction:%" Vector__XXX

EV_ EnvKlemme30: 0 [0|1] "" 1 1 DUMMY_NODE_VECTOR0 Vector__XXX;

EV_ EnvKlemme15: 0 [0|1] "" 0 2 DUMMY_NODE_VECTOR0 Vector__XXX;

CM_ SG_ 2196807762 PowerSteeringPump_Cntrl "Not currently supported";
CM_ SG_ 2196807762 ParkPawl_Cntrl "Not currently supported";
CM_ SG_ 2196807762 OnBoardChargerState "Not currently supported";
CM_ SG_ 2196807762 OnBoardChargerEnbl "Not currently supported";
CM_ SG_ 2196807762 OffBoardChargerState "Not currently supported";
CM_ SG_ 2196807762 HeaterPumpCntrl "Not currently supported";
CM_ SG_ 2196807762 Heater3Cntrl "Not currently supported";
CM_ SG_ 2196807762 Heater2Cntrl "Not currently supported";
CM_ SG_ 2196807762 Heater1Cntrl "Not currently supported";
CM_ SG_ 2196807762 OffBoardChargerDCVoltSetpnt "Not currently supported";
CM_ SG_ 2196807760 DCDC_Enbl "Not currently supported";
CM_ SG_ 2196807760 BrakeVacPumpCntrl "Not currently supported";
CM_ SG_ 2196807760 AC_Wake "Not currently supported";
CM_ SG_ 2196807760 OnBoardChargerDCVoltSetpnt "Not currently supported";
CM_ SG_ 2196807760 OnBoardChargerDCCurLim "Not currently supported";
CM_ SG_ 2196807760 OnBoardChargerACCurLim "Not currently supported";
CM_ SG_ 2196807760 OffBoardChargerDCCurLim "Not currently supported";
CM_ SG_ 2196807760 DCDC_VoltSetpnt "Not currently supported";
CM_ SG_ 2196807760 DCDC_CurLim "Not currently supported";
CM_ SG_ 2196807760 AC_SpdReq "Not currently supported";
CM_ SG_ 2196807732 LaunchTableSelect "VCU300 Only";
CM_ SG_ 2196807732 Launch_Torque_Time "VCU300 Only";
CM_ SG_ 2196807732 Launch_Torque_Multiplier "VCU300 Only";
CM_ SG_ 2196807732 Motor4_TorqueTrimTable "VCU300 Only";
CM_ SG_ 2196807732 Motor4_ReverseTorque "VCU300 Only";
CM_ SG_ 2196807730 Motor4_TqLimMultLo "VCU300 Only";
CM_ SG_ 2196807730 Motor4_TqLimMultHi "VCU300 Only";
CM_ SG_ 2196807730 Motor4_CreepTorque "VCU300 Only";
CM_ SG_ 2196807730 Motor4_TqTable "VCU300 Only";
CM_ SG_ 2196807730 Motor4_TqLimLo "VCU300 Only";
CM_ SG_ 2196807730 Motor4_TqLimHi "VCU300 Only";
CM_ SG_ 2196807728 Motor4_TorqueRequest "VCU300 Only";
CM_ SG_ 2196807728 Motor3_TorqueTrimTable "VCU300 Only";
CM_ SG_ 2196807728 Motor3_ReverseTorque "VCU300 Only";
CM_ SG_ 2196807728 Motor3_CreepTorque "VCU300 Only";
CM_ SG_ 2196807720 Motor3_TqLimMultLo "VCU300 Only";
CM_ SG_ 2196807720 Motor3_TqLimMultHi "VCU300 Only";
CM_ SG_ 2196807720 Motor3_TqTable "VCU300 Only";
CM_ SG_ 2196807720 Motor3_TqLimLo "VCU300 Only";
CM_ SG_ 2196807720 Motor3_TqLimHi "VCU300 Only";
CM_ SG_ 2196807720 Motor3_TorqueRequest "VCU300 Only";
CM_ SG_ 2196807704 Vehicle_Odometer "Not currently supported";
CM_ SG_ 2196807702 TC_Slip_Measured "Not currently supported";
CM_ SG_ 2196807702 BrakeVacPressure "Not currently supported";
CM_ SG_ 2196807684 LaunchRamp_Time "VCU300 Only";
CM_ SG_ 2196807684 LaunchTimer_Running "VCU300 Only";
CM_ SG_ 2196807684 LimMult_MC4CurrRamp_Active "VCU300 Only";
CM_ SG_ 2196807684 LimMult_MC3CurrRamp_Active "VCU300 Only";
CM_ SG_ 2196807684 LimMult_MC2CurrRamp_Active "VCU300 Only";
CM_ SG_ 2196807684 LimMult_Shift5_Tq_Active "Not currently supported";
CM_ SG_ 2196807684 LimMult_Shift4_Tq_Active "Not currently supported";
CM_ SG_ 2196807684 LimMult_Shift3_Tq_Active "Not currently supported";
CM_ SG_ 2196807684 LimMult_Shift2_Tq_Active "VCU300 Only";
CM_ SG_ 2196807684 LimMult_Shift1_Tq_Active "VCU300 Only";
CM_ SG_ 2196807684 LimMult_Motor4_Temp_Active "VCU300 Only";
CM_ SG_ 2196807684 LimMult_Motor4_SpdLo_Active "VCU300 Only";
CM_ SG_ 2196807684 LimMult_Motor3_Temp_Active "VCU300 Only";
CM_ SG_ 2196807684 LimMult_Motor3_SpdLo_Active "VCU300 Only";
CM_ SG_ 2196807684 LimMult_Motor2_Temp_Active "VCU300 Only";
CM_ SG_ 2196807684 LimMult_Motor2_SpdLo_Active "VCU300 Only";
CM_ SG_ 2196807684 LimMult_MC4Temp_Active "VCU300 Only";
CM_ SG_ 2196807684 LimMult_MC4Curr_Active "VCU300 Only";
CM_ SG_ 2196807684 LimMult_MC3Temp_Active "VCU300 Only";
CM_ SG_ 2196807684 LimMult_MC3Curr_Active "VCU300 Only";
CM_ SG_ 2196807684 LimMult_MC2Temp_Active "VCU300 Only";
CM_ SG_ 2196807684 LimMult_MC2Curr_Active "VCU300 Only";
CM_ SG_ 2196807748 Fault_WheelBar_Press2_InputLo "VCU300 Only";
CM_ SG_ 2196807748 Fault_WheelBar_Press2_InputHi "VCU300 Only";
CM_ SG_ 2196807748 Fault_WheelBar_Press1_InputLo "VCU300 Only";
CM_ SG_ 2196807748 Fault_WheelBar_Press1_InputHi "VCU300 Only";
CM_ SG_ 2196807748 Fault_Trans_Temp_InputLo "VCU300 Only";
CM_ SG_ 2196807748 Fault_Trans_Temp_InputHi "VCU300 Only";
CM_ SG_ 2196807748 Fault_Trans_Press_InputLo "VCU300 Only";
CM_ SG_ 2196807748 Fault_Trans_Press_InputHi "VCU300 Only";
CM_ SG_ 2196807748 Fault_TransBrk_Sol "VCU300 Only";
CM_ SG_ 2196807748 Fault_Shift_Sol "VCU300 Only";
CM_ SG_ 2196807748 Fault_LineLock_Sol "VCU300 Only";
CM_ SG_ 2196807748 Fault_MC5SupplyVoltageLow "Not currently supported";
CM_ SG_ 2196807748 Fault_MC4SupplyVoltageLow "VCU300 Only";
CM_ SG_ 2196807748 Fault_MC4_Contactor "VCU300 Only";
CM_ SG_ 2196807748 Fault_MC3SupplyVoltageLow "VCU300 Only";
CM_ SG_ 2196807748 Fault_MC3_Contactor "VCU300 Only";
CM_ SG_ 2196807748 Fault_MC2SupplyVoltageLow "VCU300 Only";
CM_ SG_ 2196807748 Fault_MC2_Contactor "VCU300 Only";
CM_ SG_ 2196807748 Fault_Cool_Temp2_InputLo "VCU300 Only";
CM_ SG_ 2196807748 Fault_Cool_Temp2_InputHi "VCU300 Only";
CM_ SG_ 2196807748 Fault_Cooling_Pump2 "VCU300 Only";
CM_ SG_ 2196807682 ChargeContactorCntrl "Not currently supported";
CM_ SG_ 2196807682 Acc_LightCntrl "VCU300 Only";
CM_ SG_ 2196807682 TransBrake_Switch "VCU300 Only";
CM_ SG_ 2196807682 LineLock_Switch "VCU300 Only";
CM_ SG_ 2196807682 Inertia_Switch "Not currently supported";
CM_ SG_ 2196807682 ShiftSol_Cntrl "VCU300 Only";
CM_ SG_ 2196807682 Shift_Sol2 "VCU300 Only";
CM_ SG_ 2196807682 Shift_Sol1 "VCU300 Only";
CM_ SG_ 2196807682 LineLock_Cntrl "VCU300 Only";
CM_ SG_ 2196807682 TransBrake_Cntrl "VCU300 Only";
CM_ SG_ 2196807682 Cool_Pump2_Cntrl "VCU300 Only";
CM_ SG_ 2196807682 Launch_Mode "VCU300 Only";
CM_ SG_ 2196807682 Burnout_Mode "VCU300 Only";
CM_ SG_ 2196807682 MC4_PreChgComplete "VCU300 Only";
CM_ SG_ 2196807682 MC4_PreChg_Cmd "VCU300 Only";
CM_ SG_ 2196807682 MC4_Pos_Cmd "VCU300 Only";
CM_ SG_ 2196807682 MC3_PreChgComplete "VCU300 Only";
CM_ SG_ 2196807682 MC3_PreChg_Cmd "VCU300 Only";
CM_ SG_ 2196807682 MC3_Pos_Cmd "VCU300 Only";
CM_ SG_ 2196807682 MC2_PreChgComplete "VCU300 Only";
CM_ SG_ 2196807682 MC2_PreChg_Cmd "VCU300 Only";
CM_ SG_ 2196807682 MC2_Pos_Cmd "VCU300 Only";
CM_ SG_ 2196807688 CCSetCst "Not currently supported";
CM_ SG_ 2196807688 CCRsmAcc "Not currently supported";
CM_ SG_ 2196807688 CCOn "Not currently supported";
CM_ SG_ 2196807688 CCCancel "Not currently supported";
CM_ SG_ 2196807688 Logging_Switch "VCU300 Only";
CM_ SG_ 2196807688 Acc_LightSwitch "VCU300 Only";
CM_ SG_ 2196807688 ACSwitch "Not currently supported";
CM_ SG_ 2196807688 HeaterSwitch "Not currently supported";
CM_ SG_ 2196807688 Cooling_PumpOrdSwitch "VCU300 Only";
CM_ SG_ 2196807688 Cooling_FanOrdSwitch "VCU300 Only";
CM_ SG_ 2196807700 ACPressure "Not currently supported";
CM_ SG_ 2196807700 HeaterOutletTemp "Not currently supported";
CM_ SG_ 2196807700 HeaterInletTemp "Not currently supported";
CM_ SG_ 2196807700 AmbientAirTemp "Not currently supported";
CM_ SG_ 2196807700 Coolant_Temp2 "VCU300 Only";
CM_ SG_ 2196807700 Transmission_Temp "VCU300 Only";
CM_ SG_ 2196807736 Motor_TargetSpeed "VCU300 Only";
CM_ SG_ 2196807736 LaunchTarget_Speed "VCU300 Only";
CM_ SG_ 2196807734 BurnoutTargetSpeed "VCU300 Only";
CM_ SG_ 2196807718 Motor2_TorqueTrimTable "VCU300 Only";
CM_ SG_ 2196807718 Motor2_ReverseTorque "VCU300 Only";
CM_ SG_ 2196807718 Motor2_CreepTorque "VCU300 Only";
CM_ SG_ 2196807716 Motor2_TqLimMultLo "VCU300 Only";
CM_ SG_ 2196807716 Motor2_TqLimMultHi "VCU300 Only";
CM_ SG_ 2196807716 Motor2_TqTable "VCU300 Only";
CM_ SG_ 2196807716 Motor2_TqLimLo "VCU300 Only";
CM_ SG_ 2196807716 Motor2_TqLimHi "VCU300 Only";
CM_ SG_ 2196807716 Motor2_TorqueRequest "VCU300 Only";
CM_ SG_ 2196807698 WheelBar_Press2 "VCU300 Only";
CM_ SG_ 2196807698 WheelBar_Press1 "VCU300 Only";
CM_ SG_ 2196807698 Transmission_Pressure "VCU300 Only";
CM_ SG_ 2196807680 MC4_PreChgFB "Not currently supported";
CM_ SG_ 2196807680 MC4_PosFB "Not currently supported";
CM_ SG_ 2196807680 MC4_NegFB "VCU300 Only";
CM_ SG_ 2196807680 MC4_HVDetect "VCU300 Only";
CM_ SG_ 2196807680 MC3_PreChgFB "Not currently supported";
CM_ SG_ 2196807680 MC3_PosFB "Not currently supported";
CM_ SG_ 2196807680 MC3_NegFB "VCU300 Only";
CM_ SG_ 2196807680 MC3_HVDetect "VCU300 Only";
CM_ SG_ 2196807680 MC2_PreChgFB "Not currently supported";
CM_ SG_ 2196807680 MC2_PosFB "Not currently supported";
CM_ SG_ 2196807680 MC2_NegFB "VCU300 Only";
CM_ SG_ 2196807680 MC2_HVDetect "VCU300 Only";
CM_ SG_ 2196807680 MC1_PreChgFB "Not currently supported";
CM_ SG_ 2196807680 MC1_PosFB "Not currently supported";
CM_ SG_ 2196807680 MC4_DCVoltageSafeState "VCU300 Only";
CM_ SG_ 2196807680 MC3_DCVoltageSafeState "VCU300 Only";
CM_ SG_ 2196807680 MC2_DCVoltageSafeState "VCU300 Only";
CM_ SG_ 2196807680 MC4ContEnable "VCU300 Only";
CM_ SG_ 2196807680 MC3ContEnable "VCU300 Only";
CM_ SG_ 2196807680 MC2ContEnable "VCU300 Only";
CM_ SG_ 2196807680 MC4DischargeCmd "VCU300 Only";
CM_ SG_ 2196807680 MC3DischargeCmd "VCU300 Only";
CM_ SG_ 2196807680 MC2DischargeCmd "VCU300 Only";
CM_ SG_ 2196807680 MC4Enable "VCU300 Only";
CM_ SG_ 2196807680 MC3Enable "VCU300 Only";
CM_ SG_ 2196807680 MC2Enable "VCU300 Only";
BA_DEF_ BU_  "NodeLayerModules" STRING ;
BA_DEF_ BO_  "GenMsgILSupport" ENUM  "No","Yes";
BA_DEF_  "NmBaseAddress" HEX 1024 1087;
BA_DEF_  "BusType" STRING ;
BA_DEF_ BO_  "GenMsgSendType" ENUM  "Cyclic","NotUsed","NotUsed","NotUsed","NotUsed","NotUsed","NotUsed","IfActive","NoMsgSendType","NotUsed","vector_leerstring";
BA_DEF_ SG_  "GenSigSendType" ENUM  "Cyclic","OnWrite","OnWriteWithRepetition","OnChange","OnChangeWithRepetition","IfActive","IfActiveWithRepetition","NoSigSendType","NotUsed","NotUsed","NotUsed","NotUsed","NotUsed";
BA_DEF_ SG_  "GenSigStartValue" FLOAT 0 100000000000;
BA_DEF_DEF_  "NodeLayerModules" "CANoeILNLVector.dll";
BA_DEF_DEF_  "GenMsgILSupport" "Yes";
BA_DEF_DEF_  "NmBaseAddress" 1024;
BA_DEF_DEF_  "BusType" "";
BA_DEF_DEF_  "GenMsgSendType" "NoMsgSendType";
BA_DEF_DEF_  "GenSigSendType" "Cyclic";
BA_DEF_DEF_  "GenSigStartValue" 0;
BA_ "BusType" "CAN";
BA_ "GenSigStartValue" SG_ 2196807702 BrakeVacPressure 101.323772752344;
BA_ "GenSigStartValue" SG_ 2196807700 Transmission_Temp 50;
